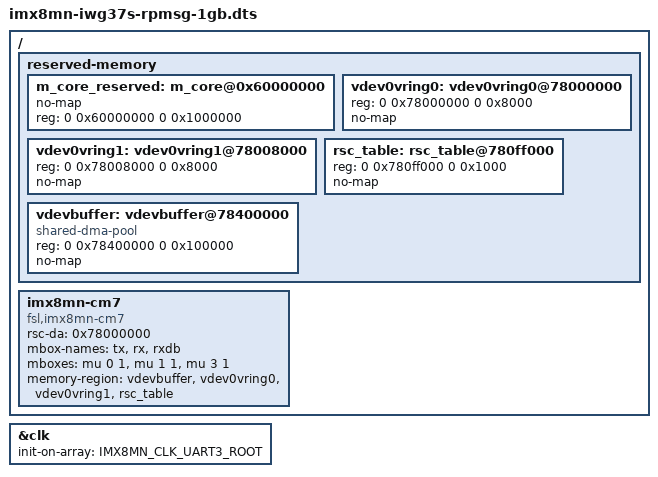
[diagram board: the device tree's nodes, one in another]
/*
 * Copyright (c) 2021-22 iWave Systems Technologies Pvt. Ltd.
 *
 * This program is free software; you can redistribute it and/or
 * modify it under the terms of the GNU General Public License
 * as published by the Free Software Foundation; either version 2
 * of the License, or (at your option) any later version.
 *
 * This program is distributed in the hope that it will be useful,
 * but WITHOUT ANY WARRANTY; without even the implied warranty of
 * MERCHANTABILITY or FITNESS FOR A PARTICULAR PURPOSE.  See the
 * GNU General Public License for more details.
 */

#include "imx8mn-iwg37s.dts"

/ {
	reserved-memory {
		#address-cells = <2>;
		#size-cells = <2>;
		ranges;

		m_core_reserved: m_core@0x60000000 {
			no-map;
			reg = <0 0x60000000 0 0x1000000>;
		};

		vdev0vring0: vdev0vring0@78000000 {
			reg = <0 0x78000000 0 0x8000>;
			no-map;
		};

		vdev0vring1: vdev0vring1@78008000 {
			reg = <0 0x78008000 0 0x8000>;
			no-map;
		};

		rsc_table: rsc_table@780ff000 {
			reg = <0 0x780ff000 0 0x1000>;
			no-map;
		};

		vdevbuffer: vdevbuffer@78400000 {
			compatible = "shared-dma-pool";
			reg = <0 0x78400000 0 0x100000>;
			no-map;
		};
	};

	imx8mn-cm7 {
		compatible = "fsl,imx8mn-cm7";
		rsc-da = <0x78000000>;
		mbox-names = "tx", "rx", "rxdb";
		mboxes = <&mu 0 1
			  &mu 1 1
			  &mu 3 1>;
		memory-region = <&vdevbuffer>, <&vdev0vring0>, <&vdev0vring1>, <&rsc_table>;
		status = "okay";
	};
};

&clk {
	init-on-array = <
	IMX8MN_CLK_UART3_ROOT
	>;
};
